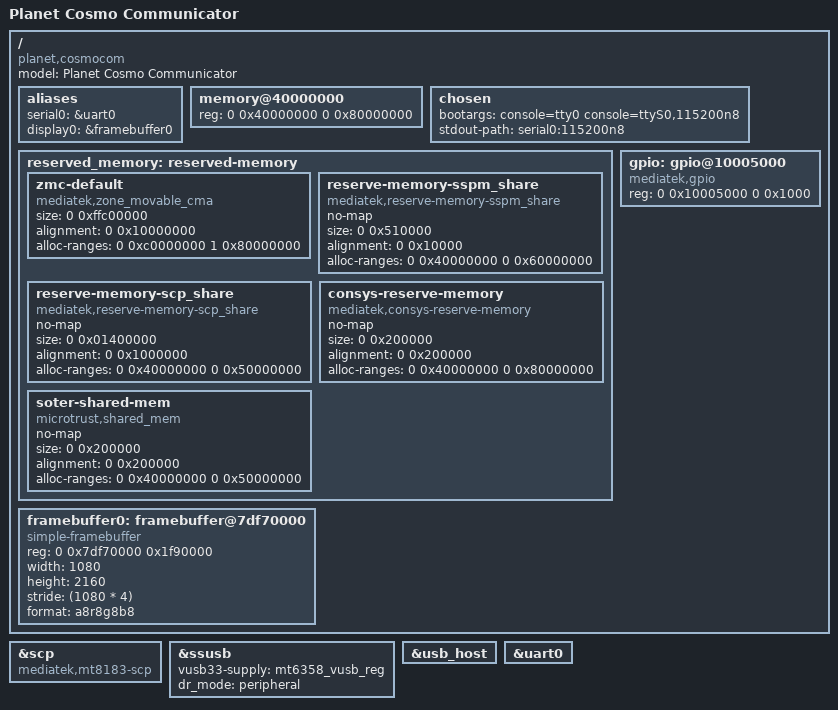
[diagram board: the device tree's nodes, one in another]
// SPDX-License-Identifier: (GPL-2.0 OR MIT)

/dts-v1/;
#include "mt8183.dtsi"
#include "mt6358.dtsi"

/ {
	model = "Planet Cosmo Communicator";
	compatible = "planet,cosmocom", "mediatek,mt6771", "mediatek,mt8183";

	aliases {
		serial0 = &uart0;
		display0 = &framebuffer0;
	};

	memory@40000000 {
		device_type = "memory";
		reg = <0 0x40000000 0 0x80000000>;
	};
	
	chosen {
		bootargs = "console=tty0 console=ttyS0,115200n8";
		stdout-path = "serial0:115200n8";
		/*stdout-path = "display0";*/
	};

	reserved_memory: reserved-memory {
		#address-cells = <2>;
		#size-cells = <2>;
		ranges;

		zmc-default {
			compatible = "mediatek,zone_movable_cma";
			size = <0 0xffc00000>;
			alignment = <0 0x10000000>;
			alloc-ranges = <0 0xc0000000 1 0x80000000>;
		};

		/*TODO: add reserved memory node here*/
		reserve-memory-sspm_share {
			compatible = "mediatek,reserve-memory-sspm_share";
			no-map;
			status = "okay";
			size = <0 0x510000>; /* 5M + 64K */
			alignment = <0 0x10000>;
			alloc-ranges = <0 0x40000000 0 0x60000000>;
		};
		reserve-memory-scp_share {
			compatible = "mediatek,reserve-memory-scp_share";
			no-map;
			size = <0 0x01400000>; /*20 MB share mem size */
			alignment = <0 0x1000000>;
			alloc-ranges = <0 0x40000000 0 0x50000000>; /*0x4000_0000~0x8FFF_FFFF*/
		};
		consys-reserve-memory {
			compatible = "mediatek,consys-reserve-memory";
			no-map;
			size = <0 0x200000>;
			alignment = <0 0x200000>;
			alloc-ranges = <0 0x40000000 0 0x80000000>;
		};
		soter-shared-mem {
			compatible = "microtrust,shared_mem";
			no-map;
			size = <0 0x200000>;
			alignment = <0 0x200000>;
			alloc-ranges = <0 0x40000000 0 0x50000000>;
		};
	};
	
    // This node is required by MediaTek's LK bootloader.
	gpio: gpio@10005000 {
		compatible = "mediatek,gpio", "syscon";
		reg = <0 0x10005000 0 0x1000>;
	};

	framebuffer0: framebuffer@7df70000 {
		compatible = "simple-framebuffer";
		reg = <0 0x7df70000 0x1f90000>;
		width = <1080>;
		height = <2160>;
		stride = <(1080 * 4)>;
		format = "a8r8g8b8";
		status = "okay";
	};
};

&scp {
	// This node is required by MediaTek's LK bootloader
	compatible = "mediatek,mt8183-scp", "mediatek,scp";
};

&ssusb {
	vusb33-supply = <&mt6358_vusb_reg>;
	dr_mode = "peripheral";
	status = "okay";
};

&usb_host {
	status = "okay";
};

&uart0 {
	/*status = "okay";*/
};
